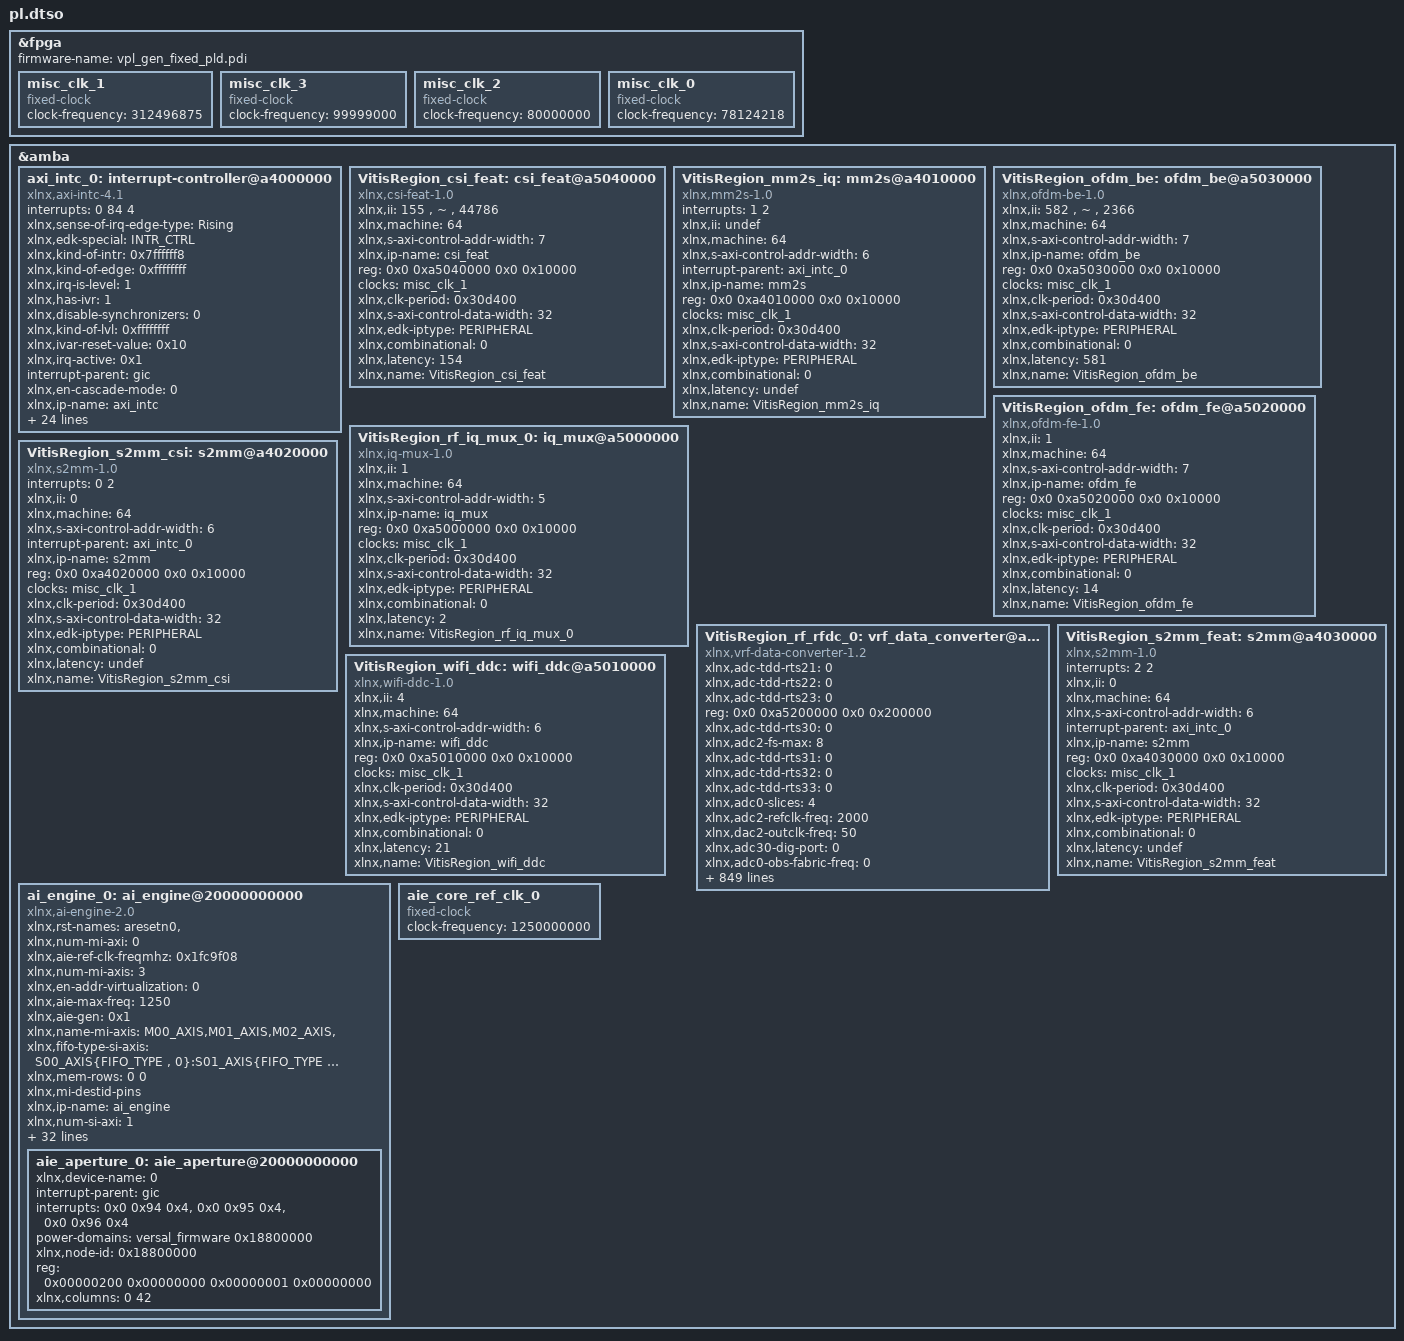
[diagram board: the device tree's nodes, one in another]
/dts-v1/;
/plugin/;
&fpga {
	firmware-name = "vpl_gen_fixed_pld.pdi";
	misc_clk_1: misc_clk_1 {
		compatible = "fixed-clock";
		clock-frequency = <312496875>;
		#clock-cells = <0>;
	};
	misc_clk_3: misc_clk_3 {
		compatible = "fixed-clock";
		clock-frequency = <99999000>;
		#clock-cells = <0>;
	};
	misc_clk_2: misc_clk_2 {
		compatible = "fixed-clock";
		clock-frequency = <80000000>;
		#clock-cells = <0>;
	};
	misc_clk_0: misc_clk_0 {
		compatible = "fixed-clock";
		clock-frequency = <78124218>;
		#clock-cells = <0>;
	};
};

&amba {
	axi_intc_0: interrupt-controller@a4000000 {
		#interrupt-cells = <2>;
		interrupts = < 0 84 4 >;
		xlnx,sense-of-irq-edge-type = "Rising";
		xlnx,edk-special = "INTR_CTRL";
		xlnx,kind-of-intr = <0x7ffffff8>;
		xlnx,kind-of-edge = <0xffffffff>;
		xlnx,irq-is-level = <1>;
		xlnx,has-ivr = <1>;
		compatible = "xlnx,axi-intc-4.1" , "xlnx,xps-intc-1.00.a";
		xlnx,disable-synchronizers = <0>;
		xlnx,kind-of-lvl = <0xffffffff>;
		xlnx,ivar-reset-value = <0x10>;
		xlnx,irq-active = <0x1>;
		interrupt-parent = <&gic>;
		xlnx,en-cascade-mode = <0>;
		xlnx,ip-name = "axi_intc";
		xlnx,has-ilr = <0>;
		reg = <0x0 0xa4000000 0x0 0x10000>;
		xlnx,addr-width = <0x20>;
		clocks = <&misc_clk_0>;
		xlnx,s-axi-aclk-freq-mhz = <0x4a814ba>;
		xlnx,num-sw-intr = <0>;
		xlnx,irq-connection = <1>;
		xlnx,num-intr-inputs = <0x1f>;
		xlnx,has-sie = <1>;
		xlnx,enable-async = <0>;
		xlnx,has-cie = <1>;
		xlnx,num-sync-ff = <2>;
		xlnx,edk-iptype = "PERIPHERAL";
		xlnx,mb-clk-not-connected = <1>;
		xlnx,has-ipr = <1>;
		xlnx,sense-of-irq-level-type = "Active_High";
		xlnx,cascade-master = <0>;
		xlnx,processor-clk-freq-mhz = <100>;
		xlnx,is-fast = <0x0>;
		clock-names = "s_axi_aclk";
		xlnx,has-fast = <0>;
		xlnx,ivar-rst-val = <0x10>;
		interrupt-controller;
		interrupt-names = "irq";
		xlnx,async-intr = <0xffffffff>;
		xlnx,name = "axi_intc_0";
	};
	VitisRegion_csi_feat: csi_feat@a5040000 {
		compatible = "xlnx,csi-feat-1.0";
		xlnx,ii = "155 , ~ , 44786";
		xlnx,machine = <64>;
		xlnx,s-axi-control-addr-width = <7>;
		xlnx,ip-name = "csi_feat";
		reg = <0x0 0xa5040000 0x0 0x10000>;
		clocks = <&misc_clk_1>;
		xlnx,clk-period = <0x30d400>;
		xlnx,s-axi-control-data-width = <32>;
		xlnx,edk-iptype = "PERIPHERAL";
		clock-names = "ap_clk";
		xlnx,combinational = <0>;
		xlnx,latency = <154>;
		xlnx,name = "VitisRegion_csi_feat";
	};
	VitisRegion_mm2s_iq: mm2s@a4010000 {
		interrupts = < 1 2 >;
		compatible = "xlnx,mm2s-1.0";
		xlnx,ii = "undef";
		xlnx,machine = <64>;
		xlnx,s-axi-control-addr-width = <6>;
		interrupt-parent = <&axi_intc_0>;
		xlnx,ip-name = "mm2s";
		reg = <0x0 0xa4010000 0x0 0x10000>;
		clocks = <&misc_clk_1>;
		xlnx,clk-period = <0x30d400>;
		xlnx,s-axi-control-data-width = <32>;
		xlnx,edk-iptype = "PERIPHERAL";
		clock-names = "ap_clk";
		interrupt-names = "interrupt";
		xlnx,combinational = <0>;
		xlnx,latency = "undef";
		xlnx,name = "VitisRegion_mm2s_iq";
	};
	VitisRegion_ofdm_be: ofdm_be@a5030000 {
		compatible = "xlnx,ofdm-be-1.0";
		xlnx,ii = "582 , ~ , 2366";
		xlnx,machine = <64>;
		xlnx,s-axi-control-addr-width = <7>;
		xlnx,ip-name = "ofdm_be";
		reg = <0x0 0xa5030000 0x0 0x10000>;
		clocks = <&misc_clk_1>;
		xlnx,clk-period = <0x30d400>;
		xlnx,s-axi-control-data-width = <32>;
		xlnx,edk-iptype = "PERIPHERAL";
		clock-names = "ap_clk";
		xlnx,combinational = <0>;
		xlnx,latency = <581>;
		xlnx,name = "VitisRegion_ofdm_be";
	};
	VitisRegion_ofdm_fe: ofdm_fe@a5020000 {
		compatible = "xlnx,ofdm-fe-1.0";
		xlnx,ii = <1>;
		xlnx,machine = <64>;
		xlnx,s-axi-control-addr-width = <7>;
		xlnx,ip-name = "ofdm_fe";
		reg = <0x0 0xa5020000 0x0 0x10000>;
		clocks = <&misc_clk_1>;
		xlnx,clk-period = <0x30d400>;
		xlnx,s-axi-control-data-width = <32>;
		xlnx,edk-iptype = "PERIPHERAL";
		clock-names = "ap_clk";
		xlnx,combinational = <0>;
		xlnx,latency = <14>;
		xlnx,name = "VitisRegion_ofdm_fe";
	};
	VitisRegion_rf_iq_mux_0: iq_mux@a5000000 {
		compatible = "xlnx,iq-mux-1.0";
		xlnx,ii = <1>;
		xlnx,machine = <64>;
		xlnx,s-axi-control-addr-width = <5>;
		xlnx,ip-name = "iq_mux";
		reg = <0x0 0xa5000000 0x0 0x10000>;
		clocks = <&misc_clk_1>;
		xlnx,clk-period = <0x30d400>;
		xlnx,s-axi-control-data-width = <32>;
		xlnx,edk-iptype = "PERIPHERAL";
		clock-names = "ap_clk";
		xlnx,combinational = <0>;
		xlnx,latency = <2>;
		xlnx,name = "VitisRegion_rf_iq_mux_0";
	};
	VitisRegion_rf_rfdc_0: vrf_data_converter@a5200000 {
		xlnx,adc-tdd-rts21 = <0>;
		xlnx,adc-tdd-rts22 = <0>;
		xlnx,adc-tdd-rts23 = <0>;
		reg = <0x0 0xa5200000 0x0 0x200000>;
		xlnx,adc-tdd-rts30 = <0>;
		xlnx,adc2-fs-max = <8>;
		xlnx,adc-tdd-rts31 = <0>;
		xlnx,adc-tdd-rts32 = <0>;
		xlnx,adc-tdd-rts33 = <0>;
		xlnx,adc0-slices = <4>;
		xlnx,adc2-refclk-freq = <2000>;
		xlnx,dac2-outclk-freq = <50>;
		xlnx,adc30-dig-port = <0>;
		xlnx,adc0-obs-fabric-freq = <0>;
		xlnx,dac2-band = <0>;
		clock-names = "m0_axis_aclk" , "s_axi_aclk";
		xlnx,adc-obs-data-width00 = <8>;
		xlnx,adc-obs-data-width01 = <8>;
		xlnx,adc-obs-data-width02 = <8>;
		xlnx,adc-coarse-mixer1-freq00 = <0>;
		xlnx,adc-obs-data-width03 = <8>;
		xlnx,adc-coarse-mixer1-freq01 = <0>;
		xlnx,adc-coarse-mixer1-freq02 = <0>;
		xlnx,adc-coarse-mixer1-freq03 = <0>;
		xlnx,adc-obs-data-width10 = <8>;
		xlnx,adc-obs-data-width11 = <8>;
		xlnx,adc-obs-data-width12 = <8>;
		xlnx,adc-coarse-mixer1-freq10 = <0>;
		xlnx,adc-obs-data-width13 = <8>;
		xlnx,mem-init-file-adc = "none";
		xlnx,adc-coarse-mixer1-freq11 = <0>;
		xlnx,adc-calopt-mode00 = <1>;
		xlnx,adc-coarse-mixer1-freq12 = <0>;
		xlnx,adc-calopt-mode01 = <1>;
		xlnx,dac3-fbdiv = <10>;
		xlnx,adc-coarse-mixer1-freq13 = <0>;
		xlnx,adc-calopt-mode02 = <1>;
		xlnx,adc-calopt-mode03 = <1>;
		xlnx,dac0-interpolation = <0>;
		xlnx,adc-obs-data-width20 = <8>;
		xlnx,adc-nco-freq00 = <0x252f88>;
		xlnx,adc-obs-data-width21 = <8>;
		xlnx,adc-nco-freq01 = <0>;
		xlnx,adc-obs-data-width22 = <8>;
		xlnx,adc-coarse-mixer1-freq20 = <0>;
		xlnx,adc-nco-freq02 = <0>;
		xlnx,adc-obs-data-width23 = <8>;
		xlnx,adc-coarse-mixer1-freq21 = <0>;
		xlnx,adc-calopt-mode10 = <1>;
		xlnx,adc-nco-freq03 = <0>;
		xlnx,dac1-vop = <24>;
		xlnx,adc-coarse-mixer1-freq22 = <0>;
		xlnx,adc-calopt-mode11 = <1>;
		xlnx,dac-mixer-mode00 = <2>;
		xlnx,adc-coarse-mixer1-freq23 = <0>;
		xlnx,adc-calopt-mode12 = <1>;
		xlnx,dac-mixer-mode01 = <2>;
		xlnx,adc-calopt-mode13 = <1>;
		xlnx,dac-mixer-mode02 = <2>;
		xlnx,dac-mixer-mode03 = <2>;
		xlnx,adc-obs-data-width30 = <8>;
		xlnx,adc-nco-freq10 = <0>;
		xlnx,adc-obs-data-width31 = <8>;
		xlnx,adc-nco-freq11 = <0>;
		xlnx,adc-obs-data-width32 = <8>;
		xlnx,dac2-fbdiv = <10>;
		xlnx,adc-coarse-mixer1-freq30 = <0>;
		xlnx,adc-nco-freq12 = <0>;
		xlnx,adc-obs-data-width33 = <8>;
		xlnx,adc-coarse-mixer1-freq31 = <0>;
		xlnx,adc-calopt-mode20 = <1>;
		xlnx,adc-nco-freq13 = <0>;
		xlnx,adc-coarse-mixer1-freq32 = <0>;
		xlnx,adc-calopt-mode21 = <1>;
		xlnx,dac-mixer-mode10 = <2>;
		xlnx,adc-coarse-mixer1-freq33 = <0>;
		xlnx,adc-calopt-mode22 = <1>;
		xlnx,dac-mixer-mode11 = <2>;
		xlnx,adc-calopt-mode23 = <1>;
		xlnx,dac-mixer-mode12 = <2>;
		xlnx,dac-mixer-mode13 = <2>;
		xlnx,adc-nco-freq20 = <0>;
		xlnx,adc-nco-freq21 = <0>;
		xlnx,adc-nco-freq22 = <0>;
		xlnx,adc-calopt-mode30 = <1>;
		xlnx,adc-nco-freq23 = <0>;
		xlnx,adc-calopt-mode31 = <1>;
		xlnx,dac-mixer-mode20 = <2>;
		xlnx,adc-calopt-mode32 = <1>;
		xlnx,adc0-fabric-freq = <80>;
		xlnx,dac-mixer-mode21 = <2>;
		xlnx,adc-calopt-mode33 = <1>;
		xlnx,dac-mixer-mode22 = <2>;
		xlnx,dac1-fbdiv = <10>;
		xlnx,dac-mixer-mode23 = <2>;
		xlnx,adc-nco-freq30 = <0>;
		xlnx,adc-nco-freq31 = <0>;
		xlnx,adc3-outclk-freq = <0x1dcd650>;
		xlnx,adc-nco-freq32 = <0>;
		xlnx,adc-nco-freq33 = <0>;
		xlnx,dac-mixer-mode30 = <2>;
		xlnx,adc23-dig-port = <0>;
		xlnx,dac-mixer-mode31 = <2>;
		xlnx,dac-mixer-mode32 = <2>;
		xlnx,dac-mixer-mode33 = <2>;
		xlnx,adc-data-type00 = <1>;
		xlnx,dac-channelizer-init-file = <0>;
		xlnx,adc-data-type01 = <0>;
		xlnx,adc-data-type02 = <0>;
		xlnx,dac0-fbdiv = <10>;
		xlnx,adc-data-type03 = <0>;
		xlnx,adc0-decimation = <40>;
		xlnx,adc-data-type10 = <0>;
		xlnx,dac3-enable = <0>;
		xlnx,adc-data-type11 = <0>;
		xlnx,adc-data-type12 = <0>;
		xlnx,adc-data-type13 = <0>;
		xlnx,adc-data-type20 = <0>;
		xlnx,adc-data-type21 = <0>;
		xlnx,adc0-link-coupling = <0>;
		xlnx,adc-data-type22 = <0>;
		xlnx,adc-data-type23 = <0>;
		xlnx,adc3-vco = <8500>;
		xlnx,adc-data-type30 = <0>;
		xlnx,adc-data-type31 = <0>;
		xlnx,adc0-clock-dist = <0>;
		xlnx,adc-data-type32 = <0>;
		xlnx,adc1-decimation = <0>;
		xlnx,adc-data-type33 = <0>;
		xlnx,adc20-dig-port = <0>;
		xlnx,adc1-fs-max = <8>;
		xlnx,adc3-sampling-rate = <2>;
		xlnx,dac0-link-coupling = <0>;
		xlnx,adc1-clock-dist = <0>;
		xlnx,adc2-decimation = <0>;
		xlnx,dac-pre-interp00 = <0>;
		xlnx,dac3-sampling-rate = <0x61a800>;
		xlnx,dac-pre-interp01 = <0>;
		xlnx,dac-pre-interp02 = <0>;
		xlnx,dac-pre-interp03 = <0>;
		xlnx,dac2-refclk-freq = <6400>;
		xlnx,dac-pre-interp10 = <0>;
		xlnx,adc-nco1-phase00 = <0>;
		xlnx,dac-pre-interp11 = <0>;
		xlnx,adc-nco1-phase01 = <0>;
		xlnx,dac-pre-interp12 = <0>;
		xlnx,adc-nco1-phase02 = <0>;
		xlnx,dac-pre-interp13 = <0>;
		xlnx,adc-nco1-phase03 = <0>;
		xlnx,adc2-clock-dist = <0>;
		xlnx,dac0-refclk-div = <1>;
		xlnx,dac-pre-interp20 = <0>;
		xlnx,adc3-decimation = <0>;
		xlnx,adc-nco1-phase10 = <0>;
		xlnx,dac-pre-interp21 = <0>;
		xlnx,adc-nco1-phase11 = <0>;
		xlnx,dac-pre-interp22 = <0>;
		xlnx,adc-nco1-phase12 = <0>;
		xlnx,dac-pre-interp23 = <0>;
		xlnx,adc-nco1-phase13 = <0>;
		xlnx,dac-pre-interp30 = <0>;
		xlnx,adc-nco1-phase20 = <0>;
		xlnx,dac-pre-interp31 = <0>;
		xlnx,adc-nco1-phase21 = <0>;
		xlnx,dac-pre-interp32 = <0>;
		xlnx,adc-nco1-phase22 = <0>;
		xlnx,dac-pre-interp33 = <0>;
		xlnx,adc-mixer-type00 = <2>;
		xlnx,adc-nco1-phase23 = <0>;
		xlnx,adc-mixer-type01 = <3>;
		xlnx,adc-mixer-type02 = <3>;
		xlnx,adc-mixer-type03 = <3>;
		xlnx,adc-nco1-phase30 = <0>;
		xlnx,adc-nco1-phase31 = <0>;
		xlnx,adc-nco1-phase32 = <0>;
		xlnx,adc-mixer-type10 = <3>;
		xlnx,adc-nco1-phase33 = <0>;
		xlnx,adc-mixer-type11 = <3>;
		xlnx,adc2-band = <0>;
		xlnx,adc-mixer-type12 = <3>;
		xlnx,adc3-clock-dist = <0>;
		xlnx,adc-mixer-type13 = <3>;
		xlnx,dac1-refclk-div = <1>;
		xlnx,adc13-dig-port = <0>;
		xlnx,adc0-pll-enable;
		xlnx,adc-mixer-type20 = <3>;
		xlnx,adc-mixer-type21 = <3>;
		xlnx,adc-mixer-type22 = <3>;
		xlnx,adc-mixer-type23 = <3>;
		xlnx,adc-mixer-type30 = <3>;
		xlnx,adc-mixer-type31 = <3>;
		xlnx,adc-mixer-type32 = <3>;
		xlnx,dac-sysref-source = <0>;
		xlnx,adc-mixer-type33 = <3>;
		xlnx,dac2-refclk-div = <1>;
		xlnx,dac0-fabric-freq = <0>;
		xlnx,adc3-refclk-freq = <2000>;
		xlnx,adc10-dig-port = <0>;
		xlnx,dac3-outclk-freq = <50>;
		xlnx,dac2-enable = <0>;
		xlnx,freq-hop-enable;
		xlnx,dac3-refclk-div = <1>;
		xlnx,adc-channelizer-init-file = <0>;
		xlnx,dac-coarse-mixer-freq00 = <0>;
		xlnx,dac-coarse-mixer-freq01 = <0>;
		xlnx,adc0-fs-max = <8>;
		xlnx,dac-coarse-mixer-freq02 = <0>;
		xlnx,mem-init-file-dac = "none";
		xlnx,dac-coarse-mixer-freq03 = <0>;
		xlnx,dac-coarse-mixer-freq10 = <0>;
		xlnx,dac-coarse-mixer-freq11 = <0>;
		xlnx,dac-coarse-mixer-freq12 = <0>;
		xlnx,dac-coarse-mixer-freq13 = <0>;
		xlnx,dac-coarse-mixer-freq20 = <0>;
		xlnx,adc2-obs-fabric-freq = <0>;
		xlnx,dac-coarse-mixer-freq21 = <0>;
		xlnx,dac3-outdiv = <1>;
		xlnx,dac-coarse-mixer-freq22 = <0>;
		xlnx,dac-coarse-mixer-freq23 = <0>;
		xlnx,dac-coarse-mixer-freq30 = <0>;
		xlnx,dac-coarse-mixer-freq31 = <0>;
		xlnx,dac-coarse-mixer-freq32 = <0>;
		xlnx,dac-coarse-mixer-freq33 = <0>;
		xlnx,adc-coarse-mixer-freq00 = <3>;
		xlnx,adc-coarse-mixer-freq01 = <0>;
		xlnx,adc1-fabric-freq = <0>;
		xlnx,adc-coarse-mixer-freq02 = <0>;
		xlnx,adc-coarse-mixer-freq03 = <0>;
		xlnx,adc-channelizer-position = <2>;
		xlnx,dac-mode00 = <0>;
		xlnx,dac-nyquist00 = <0>;
		xlnx,dac-mode01 = <0>;
		xlnx,dac-nco-phase00 = <0>;
		xlnx,dac-nyquist01 = <0>;
		xlnx,dac-mode02 = <0>;
		xlnx,dac-nco-phase01 = <0>;
		xlnx,dac-nyquist02 = <0>;
		xlnx,dac-mode03 = <0>;
		xlnx,dac-nco-phase02 = <0>;
		xlnx,dac-nyquist03 = <0>;
		xlnx,adc1-vco = <8500>;
		xlnx,adc03-dig-port = <0>;
		xlnx,dac-nco-phase03 = <0>;
		xlnx,adc-coarse-mixer-freq10 = <0>;
		xlnx,adc-coarse-mixer-freq11 = <0>;
		xlnx,adc-coarse-mixer-freq12 = <0>;
		xlnx,adc-coarse-mixer-freq13 = <0>;
		xlnx,dac-mode10 = <0>;
		xlnx,dac-nyquist10 = <0>;
		xlnx,dac-mode11 = <0>;
		xlnx,dac-nco1-phase00 = <0>;
		xlnx,dac-nco-phase10 = <0>;
		xlnx,dac-nyquist11 = <0>;
		xlnx,dac-mode12 = <0>;
		xlnx,dac-nco1-phase01 = <0>;
		xlnx,dac-nco-phase11 = <0>;
		xlnx,dac-nyquist12 = <0>;
		xlnx,dac-mode13 = <0>;
		xlnx,dac-nco1-phase02 = <0>;
		xlnx,dac-nco-phase12 = <0>;
		xlnx,dac-nyquist13 = <0>;
		xlnx,dac-nco1-phase03 = <0>;
		xlnx,dac-nco-phase13 = <0>;
		xlnx,adc-coarse-mixer-freq20 = <0>;
		xlnx,adc-coarse-mixer-freq21 = <0>;
		xlnx,adc-coarse-mixer-freq22 = <0>;
		xlnx,adc-coarse-mixer-freq23 = <0>;
		xlnx,dac-mode20 = <0>;
		xlnx,dac-nyquist20 = <0>;
		xlnx,dac-mode21 = <0>;
		xlnx,dac-nco1-phase10 = <0>;
		xlnx,dac-nco-phase20 = <0>;
		xlnx,dac-nyquist21 = <0>;
		xlnx,dac-mode22 = <0>;
		xlnx,dac-nco1-phase11 = <0>;
		xlnx,dac-nco-phase21 = <0>;
		xlnx,dac-nyquist22 = <0>;
		xlnx,dac-mode23 = <0>;
		xlnx,dac-nco1-phase12 = <0>;
		xlnx,dac-nco-phase22 = <0>;
		xlnx,dac-nyquist23 = <0>;
		xlnx,dac-nco1-phase13 = <0>;
		xlnx,dac-nco-phase23 = <0>;
		xlnx,adc-coarse-mixer-freq30 = <0>;
		xlnx,adc-coarse-mixer-freq31 = <0>;
		xlnx,dac3-slices = <4>;
		xlnx,adc-coarse-mixer-freq32 = <0>;
		xlnx,adc-coarse-mixer-freq33 = <0>;
		xlnx,dac-mode30 = <0>;
		xlnx,dac-nyquist30 = <0>;
		xlnx,dac-mode31 = <0>;
		xlnx,dac-nco1-phase20 = <0>;
		xlnx,dac-nco-phase30 = <0>;
		xlnx,dac-nyquist31 = <0>;
		xlnx,dac-mode32 = <0>;
		xlnx,dac-nco1-phase21 = <0>;
		xlnx,dac-nco-phase31 = <0>;
		xlnx,dac-nyquist32 = <0>;
		xlnx,dac-mode33 = <0>;
		xlnx,dac-nco1-phase22 = <0>;
		xlnx,dac-nco-freq00 = <0>;
		xlnx,dac-nco-phase32 = <0>;
		xlnx,dac-nyquist33 = <0>;
		xlnx,dac-mixer-type00 = <3>;
		xlnx,dac-nco1-freq00 = <0>;
		xlnx,dac-nco1-phase23 = <0>;
		xlnx,dac-nco-freq01 = <0>;
		xlnx,dac-nco-phase33 = <0>;
		xlnx,adc3-clock-source = <3>;
		xlnx,dac-mixer-type01 = <3>;
		xlnx,dac-nco1-freq01 = <0>;
		xlnx,dac-nco-freq02 = <0>;
		xlnx,adc2-sampling-rate = <2>;
		xlnx,dac-mixer-type02 = <3>;
		xlnx,dac-nco1-freq02 = <0>;
		xlnx,dac-nco-freq03 = <0>;
		xlnx,dac-mixer-type03 = <3>;
		xlnx,dac-nco1-freq03 = <0>;
		xlnx,adc31-dig-port = <0>;
		xlnx,dac-nco1-phase30 = <0>;
		xlnx,pl-clock-freq = <100>;
		xlnx,dac-nco1-phase31 = <0>;
		xlnx,dac-nco1-phase32 = <0>;
		xlnx,dac-nco-freq10 = <0>;
		xlnx,dac-mixer-type10 = <3>;
		xlnx,dac-nco1-freq10 = <0>;
		xlnx,dac-nco1-phase33 = <0>;
		xlnx,dac-nco-freq11 = <0>;
		xlnx,adc00-dig-port = <1>;
		xlnx,dac-mixer-type11 = <3>;
		xlnx,dac-nco1-freq11 = <0>;
		xlnx,dac-nco-freq12 = <0>;
		xlnx,edk-iptype = "PERIPHERAL";
		xlnx,dac-mixer-type12 = <3>;
		xlnx,dac-nco1-freq12 = <0>;
		xlnx,dac-nco-freq13 = <0>;
		xlnx,dac-mixer-type13 = <3>;
		xlnx,dac-nco1-freq13 = <0>;
		xlnx,dac-nco-freq20 = <0>;
		xlnx,dac-mixer-type20 = <3>;
		xlnx,dac-nco1-freq20 = <0>;
		xlnx,dac-nco-freq21 = <0>;
		xlnx,dac-mixer-type21 = <3>;
		xlnx,dac-nco1-freq21 = <0>;
		xlnx,dac-nco-freq22 = <0>;
		xlnx,dac-mixer-type22 = <3>;
		xlnx,dac-nco1-freq22 = <0>;
		xlnx,dac-nco-freq23 = <0>;
		xlnx,dac-mixer-type23 = <3>;
		xlnx,dac-nco1-freq23 = <0>;
		xlnx,adc2-clock-source = <2>;
		xlnx,adc2-dlc = <0>;
		xlnx,dac2-sampling-rate = <0x61a800>;
		xlnx,dac-nco-freq30 = <0>;
		xlnx,dac-mixer-type30 = <3>;
		xlnx,dac-nco1-freq30 = <0>;
		xlnx,dac-nco-freq31 = <0>;
		xlnx,dac-mixer-type31 = <3>;
		xlnx,dac-nco1-freq31 = <0>;
		xlnx,dac-nco-freq32 = <0>;
		xlnx,dac-mixer-type32 = <3>;
		xlnx,dac-nco1-freq32 = <0>;
		xlnx,dac-nco-freq33 = <0>;
		xlnx,dac2-vco = <8500>;
		xlnx,dac-mixer-type33 = <3>;
		xlnx,dac-nco1-freq33 = <0>;
		xlnx,dac1-band = <0>;
		xlnx,dac1-enable = <0>;
		xlnx,elaboration-dir = <0>;
		xlnx,adc1-clock-source = <1>;
		compatible = "xlnx,vrf-data-converter-1.2";
		xlnx,dac3-refclk-freq = <6400>;
		xlnx,dac-debug = <0>;
		xlnx,dac-second-stage-duc-mix00 = <0>;
		xlnx,dac-second-stage-duc-mix01 = <0>;
		xlnx,dac-second-stage-duc-mix02 = <0>;
		xlnx,dac-second-stage-duc-mix03 = <0>;
		xlnx,dac-second-stage-duc-mix10 = <0>;
		xlnx,adc3-enable = <0>;
		xlnx,dac-second-stage-duc-mix11 = <0>;
		xlnx,dac-second-stage-duc-mix12 = <0>;
		xlnx,dac-second-stage-duc-mix13 = <0>;
		xlnx,adc0-clock-source = <0>;
		xlnx,dac-second-stage-duc-mix20 = <0>;
		xlnx,dac-second-stage-duc-mix21 = <0>;
		xlnx,dac-second-stage-duc-mix22 = <0>;
		xlnx,dac-second-stage-duc-mix23 = <0>;
		xlnx,dac-second-stage-duc-mix30 = <0>;
		xlnx,dac-second-stage-duc-mix31 = <0>;
		xlnx,dac2-outdiv = <1>;
		xlnx,dac-second-stage-duc-mix32 = <0>;
		xlnx,dac-second-stage-duc-mix33 = <0>;
		xlnx,adc0-outclk-freq = <100>;
		xlnx,adc-obs-decimation-mode00 = <1>;
		xlnx,adc-obs-decimation-mode01 = <0>;
		xlnx,adc-obs-decimation-mode02 = <0>;
		xlnx,adc-obs-decimation-mode03 = <0>;
		xlnx,adc-obs-decimation-mode10 = <1>;
		xlnx,adc-obs-decimation-mode11 = <1>;
		xlnx,adc-obs-decimation-mode12 = <1>;
		xlnx,adc-obs-decimation-mode13 = <1>;
		xlnx,vnc-enables = <110000>;
		xlnx,adc21-dig-port = <0>;
		xlnx,adc-obs-decimation-mode20 = <1>;
		xlnx,adc-obs-decimation-mode21 = <1>;
		xlnx,dac1-fabric-freq = <0>;
		xlnx,dac3-interpolation = <0>;
		xlnx,adc-obs-decimation-mode22 = <1>;
		xlnx,adc-obs-decimation-mode23 = <1>;
		xlnx,adc-obs-decimation-mode30 = <1>;
		xlnx,adc-band-self00 = <0>;
		xlnx,adc-obs-decimation-mode31 = <1>;
		xlnx,adc-band-self01 = <1>;
		xlnx,adc-obs-decimation-mode32 = <1>;
		xlnx,dac2-slices = <4>;
		xlnx,adc-band-self02 = <1>;
		xlnx,adc-obs-decimation-mode33 = <1>;
		xlnx,adc-band-self03 = <1>;
		xlnx,adc-dither00;
		xlnx,adc-dither01;
		xlnx,adc-dither02;
		xlnx,adc-dither03;
		xlnx,adc-band-self10 = <1>;
		xlnx,adc-band-self11 = <1>;
		xlnx,adc-band-self12 = <1>;
		xlnx,dac2-vop = <24>;
		xlnx,adc-band-self13 = <1>;
		xlnx,adc-dither10;
		xlnx,adc-dither11;
		xlnx,adc-dither12;
		xlnx,adc-dither13;
		xlnx,adc-band-self20 = <1>;
		xlnx,adc-band-self21 = <1>;
		xlnx,adc-band-self22 = <1>;
		xlnx,adc-band-self23 = <1>;
		xlnx,adc-dither20;
		xlnx,adc-dither21;
		xlnx,adc-dither22;
		xlnx,adc-dither23;
		xlnx,adc-band-self30 = <1>;
		xlnx,adc-band-self31 = <1>;
		xlnx,adc-band-self32 = <1>;
		xlnx,adc-band-self33 = <1>;
		xlnx,adc-dither30;
		xlnx,adc-dither31;
		xlnx,adc-dither32;
		xlnx,adc-dither33;
		xlnx,dac0-enable = <0>;
		xlnx,adc3-link-coupling = <0>;
		xlnx,adc2-fabric-freq = <0>;
		xlnx,name = "VitisRegion_rf_rfdc_0";
		xlnx,adc-data-width00 = <2>;
		xlnx,adc-data-width01 = <13>;
		xlnx,adc-data-width02 = <13>;
		xlnx,adc2-enable = <0>;
		xlnx,adc-data-width03 = <13>;
		xlnx,adc3-fbdiv = <10>;
		xlnx,adc1-band = <0>;
		xlnx,dac3-link-coupling = <0>;
		xlnx,adc-data-width10 = <8>;
		xlnx,adc-data-width11 = <8>;
		xlnx,adc-data-width12 = <8>;
		xlnx,adc-data-width13 = <8>;
		xlnx,adc1-sampling-rate = <2>;
		xlnx,adc-data-width20 = <8>;
		xlnx,adc-data-width21 = <8>;
		xlnx,adc-data-width22 = <8>;
		xlnx,adc0-dlc = <0>;
		xlnx,adc-data-width23 = <8>;
		xlnx,dac1-outdiv = <1>;
		xlnx,adc2-fbdiv = <10>;
		xlnx,adc-debug = <0>;
		xlnx,dac0-vco = <8500>;
		xlnx,adc-data-width30 = <8>;
		xlnx,adc-data-width31 = <8>;
		xlnx,adc-data-width32 = <8>;
		xlnx,adc-data-width33 = <8>;
		xlnx,adc11-dig-port = <0>;
		xlnx,dac-data-type00 = <0>;
		xlnx,dac-tdd-rts00 = <0>;
		xlnx,dac-data-type01 = <0>;
		xlnx,dac-tdd-rts01 = <0>;
		xlnx,dac-data-type02 = <0>;
		xlnx,dac-tdd-rts02 = <0>;
		xlnx,adc1-fbdiv = <10>;
		xlnx,dac-data-type03 = <0>;
		xlnx,dac-tdd-rts03 = <0>;
		xlnx,dac1-sampling-rate = <0x61a800>;
		xlnx,dac-data-type10 = <0>;
		xlnx,dac-tdd-rts10 = <0>;
		xlnx,dac-data-type11 = <0>;
		xlnx,dac-tdd-rts11 = <0>;
		xlnx,dac-data-type12 = <0>;
		xlnx,dac-tdd-rts12 = <0>;
		xlnx,dac-data-type13 = <0>;
		xlnx,dac-tdd-rts13 = <0>;
		xlnx,adc3-outdiv = <1>;
		xlnx,adc0-refclk-freq = <200>;
		xlnx,adc0-fbdiv = <64>;
		xlnx,dac-data-type20 = <0>;
		xlnx,dac-tdd-rts20 = <0>;
		xlnx,dac-data-type21 = <0>;
		xlnx,dac-tdd-rts21 = <0>;
		xlnx,dac0-outclk-freq = <50>;
		xlnx,dac-data-type22 = <0>;
		xlnx,dac-tdd-rts22 = <0>;
		xlnx,dac-data-type23 = <0>;
		xlnx,dac-tdd-rts23 = <0>;
		xlnx,dac3-fs-max = <16>;
		xlnx,dac-data-type30 = <0>;
		xlnx,dac-tdd-rts30 = <0>;
		xlnx,dac0-clock-dist = <0>;
		xlnx,dac-data-type31 = <0>;
		xlnx,dac-tdd-rts31 = <0>;
		xlnx,dac-data-type32 = <0>;
		xlnx,dac-tdd-rts32 = <0>;
		xlnx,dac-data-type33 = <0>;
		xlnx,dac-tdd-rts33 = <0>;
		xlnx,dac1-slices = <4>;
		xlnx,preset = "None";
		xlnx,dac1-clock-dist = <0>;
		xlnx,adc-first-stage-ddc-decimation00 = <1>;
		xlnx,adc-first-stage-ddc-decimation01 = <1>;
		xlnx,adc-first-stage-ddc-decimation02 = <1>;
		xlnx,adc3-slices = <4>;
		xlnx,adc-first-stage-ddc-decimation03 = <1>;
		xlnx,dac-interpolation-mode00 = <0>;
		xlnx,dac-interpolation-mode01 = <0>;
		xlnx,adc-first-stage-ddc-decimation10 = <0>;
		xlnx,dac-interpolation-mode02 = <0>;
		xlnx,adc-first-stage-ddc-decimation11 = <0>;
		xlnx,dac-interpolation-mode03 = <0>;
		xlnx,adc-first-stage-ddc-decimation12 = <0>;
		xlnx,adc-decimation-mode00 = <40>;
		xlnx,adc-first-stage-ddc-decimation13 = <0>;
		xlnx,adc-decimation-mode01 = <0>;
		xlnx,adc-decimation-mode02 = <0>;
		xlnx,adc-decimation-mode03 = <0>;
		xlnx,dac-interpolation-mode10 = <0>;
		xlnx,dac-interpolation-mode11 = <0>;
		xlnx,adc-first-stage-ddc-decimation20 = <0>;
		xlnx,dac-interpolation-mode12 = <0>;
		xlnx,adc-first-stage-ddc-decimation21 = <0>;
		xlnx,dac-interpolation-mode13 = <0>;
		xlnx,adc-first-stage-ddc-decimation22 = <0>;
		xlnx,dac2-clock-dist = <0>;
		xlnx,adc-decimation-mode10 = <0>;
		xlnx,adc-first-stage-ddc-decimation23 = <0>;
		xlnx,adc-decimation-mode11 = <0>;
		xlnx,adc-decimation-mode12 = <0>;
		xlnx,adc-decimation-mode13 = <0>;
		xlnx,dac-interpolation-mode20 = <0>;
		xlnx,dac-interpolation-mode21 = <0>;
		xlnx,adc-first-stage-ddc-decimation30 = <0>;
		xlnx,dac-interpolation-mode22 = <0>;
		xlnx,adc-first-stage-ddc-decimation31 = <0>;
		xlnx,dac-interpolation-mode23 = <0>;
		xlnx,adc-first-stage-ddc-decimation32 = <0>;
		xlnx,adc-decimation-mode20 = <0>;
		xlnx,adc-first-stage-ddc-decimation33 = <0>;
		xlnx,adc-decimation-mode21 = <0>;
		xlnx,adc-decimation-mode22 = <0>;
		xlnx,adc-decimation-mode23 = <0>;
		xlnx,dac-interpolation-mode30 = <0>;
		xlnx,adc1-outclk-freq = <0x1dcd650>;
		xlnx,dac-interpolation-mode31 = <0>;
		xlnx,dac-interpolation-mode32 = <0>;
		xlnx,dac-interpolation-mode33 = <0>;
		xlnx,adc-decimation-mode30 = <0>;
		xlnx,dac2-interpolation = <0>;
		xlnx,adc-decimation-mode31 = <0>;
		xlnx,adc1-obs-fabric-freq = <0>;
		xlnx,adc-decimation-mode32 = <0>;
		xlnx,adc-decimation-mode33 = <0>;
		xlnx,dac0-vop = <24>;
		xlnx,adc1-enable = <0>;
		xlnx,dac3-clock-dist = <0>;
		xlnx,adc32-dig-port = <0>;
		xlnx,adc01-dig-port = <0>;
		xlnx,dac2-fabric-freq = <0>;
		xlnx,dac3-clock-source = <7>;
		xlnx,vnc-include-fs2-change;
		xlnx,dac-second-stage-duc00 = <0>;
		xlnx,dac-second-stage-duc01 = <0>;
		xlnx,dac-data-width00 = <16>;
		xlnx,dac-second-stage-duc02 = <0>;
		xlnx,dac-data-width01 = <16>;
		xlnx,dac-decoder-mode00 = <1>;
		xlnx,dac-second-stage-duc03 = <0>;
		xlnx,dac-data-width02 = <16>;
		xlnx,dac-decoder-mode01 = <1>;
		xlnx,dac-data-width03 = <16>;
		xlnx,dac-decoder-mode02 = <1>;
		xlnx,dac0-outdiv = <1>;
		xlnx,dac-decoder-mode03 = <1>;
		xlnx,dac-vop-mode = <1>;
		xlnx,dac-second-stage-duc10 = <0>;
		xlnx,dac-second-stage-duc11 = <0>;
		xlnx,dac-data-width10 = <16>;
		xlnx,dac-second-stage-duc12 = <0>;
		xlnx,dac-data-width11 = <16>;
		xlnx,dac-decoder-mode10 = <1>;
		xlnx,dac-second-stage-duc13 = <0>;
		xlnx,ip-name = "vrf_data_converter";
		xlnx,dac-data-width12 = <16>;
		xlnx,dac-decoder-mode11 = <1>;
		xlnx,dac-data-width13 = <16>;
		xlnx,dac-decoder-mode12 = <1>;
		xlnx,adc-slice00-enable;
		xlnx,dac-decoder-mode13 = <1>;
		xlnx,dac-second-stage-duc20 = <0>;
		xlnx,dac-second-stage-duc21 = <0>;
		xlnx,dac-data-width20 = <16>;
		xlnx,dac-second-stage-duc22 = <0>;
		xlnx,dac-data-width21 = <16>;
		xlnx,dac-decoder-mode20 = <1>;
		xlnx,dac-second-stage-duc23 = <0>;
		xlnx,dac-coarse-mixer1-freq00 = <0>;
		xlnx,dac-data-width22 = <16>;
		xlnx,dac-decoder-mode21 = <1>;
		xlnx,dac2-clock-source = <6>;
		xlnx,dac-coarse-mixer1-freq01 = <0>;
		xlnx,dac-data-width23 = <16>;
		xlnx,dac-decoder-mode22 = <1>;
		xlnx,dac-coarse-mixer1-freq02 = <0>;
		xlnx,dac-decoder-mode23 = <1>;
		xlnx,dac-coarse-mixer1-freq03 = <0>;
		xlnx,dac3-band = <0>;
		xlnx,dac-second-stage-duc30 = <0>;
		xlnx,dac-second-stage-duc31 = <0>;
		xlnx,dac-data-width30 = <16>;
		xlnx,dac-second-stage-duc32 = <0>;
		xlnx,dac-data-width31 = <16>;
		xlnx,dac-decoder-mode30 = <1>;
		xlnx,dac-second-stage-duc33 = <0>;
		xlnx,adc-first-stage-ddc-mix00 = <7>;
		xlnx,dac-coarse-mixer1-freq10 = <0>;
		xlnx,dac-data-width32 = <16>;
		xlnx,dac-decoder-mode31 = <1>;
		xlnx,adc2-outdiv = <1>;
		xlnx,adc-first-stage-ddc-mix01 = <7>;
		xlnx,dac0-band = <0>;
		xlnx,dac-coarse-mixer1-freq11 = <0>;
		xlnx,dac-data-width33 = <16>;
		xlnx,dac-decoder-mode32 = <1>;
		xlnx,adc-first-stage-ddc-mix02 = <7>;
		xlnx,dac-coarse-mixer1-freq12 = <0>;
		xlnx,dac-decoder-mode33 = <1>;
		xlnx,adc-first-stage-ddc-mix03 = <7>;
		xlnx,dac-coarse-mixer1-freq13 = <0>;
		xlnx,adc-first-stage-ddc-mix10 = <7>;
		xlnx,dac-coarse-mixer1-freq20 = <0>;
		xlnx,rf-analyzer = <0>;
		xlnx,adc2-link-coupling = <0>;
		xlnx,adc-first-stage-ddc-mix11 = <7>;
		xlnx,dac2-fs-max = <16>;
		xlnx,dac-coarse-mixer1-freq21 = <0>;
		xlnx,adc0-refclk-div = <1>;
		xlnx,adc-first-stage-ddc-mix12 = <7>;
		xlnx,dac-coarse-mixer1-freq22 = <0>;
		xlnx,adc-first-stage-ddc-mix13 = <7>;
		xlnx,dac-coarse-mixer1-freq23 = <0>;
		xlnx,adc2-vco = <8500>;
		xlnx,dac1-clock-source = <5>;
		clocks = <&misc_clk_2>, <&misc_clk_3>;
		xlnx,adc-nyquist00 = <0>;
		xlnx,adc-first-stage-ddc-mix20 = <7>;
		xlnx,adc-nyquist01 = <0>;
		xlnx,dac-coarse-mixer1-freq30 = <0>;
		xlnx,adc-first-stage-ddc-mix21 = <7>;
		xlnx,adc-nyquist02 = <0>;
		xlnx,dac-coarse-mixer1-freq31 = <0>;
		xlnx,adc-first-stage-ddc-mix22 = <7>;
		xlnx,adc-nyquist03 = <0>;
		xlnx,dac-coarse-mixer1-freq32 = <0>;
		xlnx,adc-first-stage-ddc-mix23 = <7>;
		xlnx,dac-coarse-mixer1-freq33 = <0>;
		xlnx,dac0-refclk-freq = <6400>;
		xlnx,dac0-slices = <4>;
		xlnx,adc-nyquist10 = <0>;
		xlnx,adc-first-stage-ddc-mix30 = <7>;
		xlnx,adc-nyquist11 = <0>;
		xlnx,adc-first-stage-ddc-mix31 = <7>;
		xlnx,adc-nyquist12 = <0>;
		xlnx,adc-first-stage-ddc-mix32 = <7>;
		xlnx,adc-nyquist13 = <0>;
		xlnx,adc-first-stage-ddc-mix33 = <7>;
		xlnx,dac2-link-coupling = <0>;
		xlnx,adc-nyquist20 = <0>;
		xlnx,calibration-time = <10>;
		xlnx,adc1-refclk-div = <1>;
		xlnx,adc-nyquist21 = <0>;
		xlnx,adc-nyquist22 = <0>;
		xlnx,adc-nyquist23 = <0>;
		xlnx,dac0-clock-source = <4>;
		xlnx,adc0-sampling-rate = <0x61a800>;
		xlnx,adc3-fabric-freq = <0>;
		xlnx,adc-nyquist30 = <0>;
		xlnx,adc-nyquist31 = <0>;
		xlnx,adc-nyquist32 = <0>;
		xlnx,axiclk-freq = <100>;
		xlnx,adc-nyquist33 = <0>;
		xlnx,adc2-slices = <4>;
		xlnx,adc2-refclk-div = <1>;
		xlnx,dac0-sampling-rate = <0x61a800>;
		xlnx,adc3-dlc = <0>;
		xlnx,adc-first-stage-ddc00 = <0>;
		xlnx,adc22-dig-port = <0>;
		xlnx,adc-first-stage-ddc01 = <0>;
		xlnx,adc-first-stage-ddc02 = <0>;
		xlnx,dac3-vco = <8500>;
		xlnx,adc-first-stage-ddc03 = <0>;
		xlnx,adc-first-stage-ddc10 = <0>;
		xlnx,adc-first-stage-ddc11 = <0>;
		xlnx,adc-first-stage-ddc12 = <0>;
		xlnx,adc-first-stage-ddc13 = <0>;
		xlnx,adc-mode00 = <1>;
		xlnx,adc-mode01 = <0>;
		xlnx,adc-mode02 = <0>;
		xlnx,adc-mode03 = <0>;
		xlnx,adc3-refclk-div = <1>;
		xlnx,adc-first-stage-ddc20 = <0>;
		xlnx,adc-first-stage-ddc21 = <0>;
		xlnx,adc-first-stage-ddc22 = <0>;
		xlnx,adc-first-stage-ddc23 = <0>;
		xlnx,adc-mode10 = <0>;
		xlnx,adc0-enable = <1>;
		xlnx,adc-mode11 = <0>;
		xlnx,adc-mode12 = <0>;
		xlnx,adc-mode13 = <0>;
		xlnx,adc1-refclk-freq = <2000>;
		xlnx,production-simulation = <0>;
		xlnx,adc-first-stage-ddc30 = <0>;
		xlnx,adc-first-stage-ddc31 = <0>;
		xlnx,adc-first-stage-ddc32 = <0>;
		xlnx,dac1-outclk-freq = <50>;
		xlnx,adc-first-stage-ddc33 = <0>;
		xlnx,adc-mode20 = <0>;
		xlnx,adc-mode21 = <0>;
		xlnx,adc-mode22 = <0>;
		xlnx,disable-bg-cal-en = <1>;
		xlnx,adc-mode23 = <0>;
		xlnx,silicon-revision = <0>;
		xlnx,adc-mode30 = <0>;
		xlnx,adc-mode31 = <0>;
		xlnx,adc-mode32 = <0>;
		xlnx,adc-mode33 = <0>;
		xlnx,adc1-outdiv = <1>;
		xlnx,dac1-fs-max = <16>;
		xlnx,adc-nco-phase00 = <0>;
		xlnx,adc-nco-phase01 = <0>;
		xlnx,adc-nco-phase02 = <0>;
		xlnx,adc-nco-phase03 = <0>;
		xlnx,adc-nco-phase10 = <0>;
		xlnx,adc-nco-phase11 = <0>;
		xlnx,adc-nco-phase12 = <0>;
		xlnx,dac1-interpolation = <0>;
		xlnx,adc-nco-phase13 = <0>;
		xlnx,vnc-include-ois-change;
		xlnx,adc3-band = <0>;
		xlnx,adc-nco-phase20 = <0>;
		xlnx,adc-nco-phase21 = <0>;
		xlnx,adc-nco-phase22 = <0>;
		xlnx,adc-nco-phase23 = <0>;
		xlnx,adc0-band = <0>;
		xlnx,adc3-fs-max = <8>;
		xlnx,adc2-outclk-freq = <0x1dcd650>;
		xlnx,adc-nco-phase30 = <0>;
		xlnx,adc-nco-phase31 = <0>;
		xlnx,dac-second-stage-duc-interpolation00 = <0>;
		xlnx,adc-nco-phase32 = <0>;
		xlnx,dac-second-stage-duc-interpolation01 = <0>;
		xlnx,adc-nco1-freq00 = <0>;
		xlnx,adc-nco-phase33 = <0>;
		xlnx,dac-second-stage-duc-interpolation02 = <0>;
		xlnx,adc-nco1-freq01 = <0>;
		xlnx,dac-second-stage-duc-interpolation03 = <0>;
		xlnx,adc-nco1-freq02 = <0>;
		xlnx,adc-nco1-freq03 = <0>;
		xlnx,dac3-vop = <24>;
		xlnx,adc12-dig-port = <0>;
		xlnx,adc-sysref-source = <0>;
		xlnx,ip-type = <3>;
		xlnx,dac-second-stage-duc-interpolation10 = <0>;
		xlnx,adc1-slices = <4>;
		xlnx,dac-second-stage-duc-interpolation11 = <0>;
		xlnx,adc-nco1-freq10 = <0>;
		xlnx,dac-second-stage-duc-interpolation12 = <0>;
		xlnx,adc-nco1-freq11 = <0>;
		xlnx,dac-second-stage-duc-interpolation13 = <0>;
		xlnx,adc-nco1-freq12 = <0>;
		xlnx,adc-nco1-freq13 = <0>;
		xlnx,dac-second-stage-duc-interpolation20 = <0>;
		xlnx,dac3-fabric-freq = <0>;
		xlnx,high-speed-adc = <1>;
		xlnx,dac-second-stage-duc-interpolation21 = <0>;
		xlnx,adc-nco1-freq20 = <0>;
		xlnx,dac-second-stage-duc-interpolation22 = <0>;
		xlnx,adc-nco1-freq21 = <0>;
		xlnx,dac-second-stage-duc-interpolation23 = <0>;
		xlnx,adc-nco1-freq22 = <0>;
		xlnx,adc-nco1-freq23 = <0>;
		xlnx,dac-second-stage-duc-interpolation30 = <0>;
		xlnx,dac-second-stage-duc-interpolation31 = <0>;
		xlnx,adc-nco1-freq30 = <0>;
		xlnx,dac-second-stage-duc-interpolation32 = <0>;
		xlnx,adc0-vco = <12800>;
		xlnx,adc-nco1-freq31 = <0>;
		xlnx,dac-second-stage-duc-interpolation33 = <0>;
		xlnx,adc-nco1-freq32 = <0>;
		xlnx,adc-nco1-freq33 = <0>;
		xlnx,adc3-obs-fabric-freq = <0>;
		xlnx,adc1-link-coupling = <0>;
		xlnx,adc-mixer-mode00 = <0>;
		xlnx,adc-mixer-mode01 = <2>;
		xlnx,adc-mixer-mode02 = <2>;
		xlnx,adc-mixer-mode03 = <2>;
		xlnx,dac-band-self00 = <1>;
		xlnx,dac-band-self01 = <1>;
		xlnx,dac-band-self02 = <1>;
		xlnx,dac-band-self03 = <1>;
		xlnx,adc-mixer-mode10 = <2>;
		xlnx,adc-mixer-mode11 = <2>;
		xlnx,analog-detection = <1>;
		xlnx,adc-mixer-mode12 = <2>;
		xlnx,adc-mixer-mode13 = <2>;
		xlnx,dac-band-self10 = <1>;
		xlnx,dac-band-self11 = <1>;
		xlnx,dac-band-self12 = <1>;
		xlnx,dac-band-self13 = <1>;
		xlnx,adc-mixer-mode20 = <2>;
		xlnx,adc-mixer-mode21 = <2>;
		xlnx,adc-mixer-mode22 = <2>;
		xlnx,adc-mixer-mode23 = <2>;
		xlnx,dac1-link-coupling = <0>;
		xlnx,dac-band-self20 = <1>;
		xlnx,dac-band-self21 = <1>;
		xlnx,dac-band-self22 = <1>;
		xlnx,dac-band-self23 = <1>;
		xlnx,adc-mixer-mode30 = <2>;
		xlnx,adc-mixer-mode31 = <2>;
		xlnx,dac1-refclk-freq = <6400>;
		xlnx,adc-mixer-mode32 = <2>;
		xlnx,adc-mixer-mode33 = <2>;
		xlnx,dac-band-self30 = <1>;
		xlnx,dac-band-self31 = <1>;
		xlnx,dac-band-self32 = <1>;
		xlnx,dac-band-self33 = <1>;
		xlnx,adc1-dlc = <0>;
		xlnx,dac-channelizer-position = <0>;
		xlnx,dac1-vco = <8500>;
		xlnx,adc0-outdiv = <2>;
		xlnx,adc-tdd-rts00 = <0>;
		xlnx,adc-tdd-rts01 = <0>;
		xlnx,adc-tdd-rts02 = <0>;
		xlnx,dac0-fs-max = <16>;
		xlnx,adc-tdd-rts03 = <0>;
		xlnx,adc-tdd-rts10 = <0>;
		xlnx,adc33-dig-port = <0>;
		xlnx,adc-tdd-rts11 = <0>;
		xlnx,adc-tdd-rts12 = <0>;
		xlnx,adc-tdd-rts13 = <0>;
		xlnx,adc02-dig-port = <0>;
		xlnx,adc-tdd-rts20 = <0>;
		xlnx,component-name = "vitis_design_rfdc_0_0";
	};
	VitisRegion_s2mm_csi: s2mm@a4020000 {
		interrupts = < 0 2 >;
		compatible = "xlnx,s2mm-1.0";
		xlnx,ii = <0>;
		xlnx,machine = <64>;
		xlnx,s-axi-control-addr-width = <6>;
		interrupt-parent = <&axi_intc_0>;
		xlnx,ip-name = "s2mm";
		reg = <0x0 0xa4020000 0x0 0x10000>;
		clocks = <&misc_clk_1>;
		xlnx,clk-period = <0x30d400>;
		xlnx,s-axi-control-data-width = <32>;
		xlnx,edk-iptype = "PERIPHERAL";
		clock-names = "ap_clk";
		interrupt-names = "interrupt";
		xlnx,combinational = <0>;
		xlnx,latency = "undef";
		xlnx,name = "VitisRegion_s2mm_csi";
	};
	VitisRegion_s2mm_feat: s2mm@a4030000 {
		interrupts = < 2 2 >;
		compatible = "xlnx,s2mm-1.0";
		xlnx,ii = <0>;
		xlnx,machine = <64>;
		xlnx,s-axi-control-addr-width = <6>;
		interrupt-parent = <&axi_intc_0>;
		xlnx,ip-name = "s2mm";
		reg = <0x0 0xa4030000 0x0 0x10000>;
		clocks = <&misc_clk_1>;
		xlnx,clk-period = <0x30d400>;
		xlnx,s-axi-control-data-width = <32>;
		xlnx,edk-iptype = "PERIPHERAL";
		clock-names = "ap_clk";
		interrupt-names = "interrupt";
		xlnx,combinational = <0>;
		xlnx,latency = "undef";
		xlnx,name = "VitisRegion_s2mm_feat";
	};
	VitisRegion_wifi_ddc: wifi_ddc@a5010000 {
		compatible = "xlnx,wifi-ddc-1.0";
		xlnx,ii = <4>;
		xlnx,machine = <64>;
		xlnx,s-axi-control-addr-width = <6>;
		xlnx,ip-name = "wifi_ddc";
		reg = <0x0 0xa5010000 0x0 0x10000>;
		clocks = <&misc_clk_1>;
		xlnx,clk-period = <0x30d400>;
		xlnx,s-axi-control-data-width = <32>;
		xlnx,edk-iptype = "PERIPHERAL";
		clock-names = "ap_clk";
		xlnx,combinational = <0>;
		xlnx,latency = <21>;
		xlnx,name = "VitisRegion_wifi_ddc";
	};
	ai_engine_0: ai_engine@20000000000 {
		xlnx,rst-names = "aresetn0,";
		xlnx,num-mi-axi = <0>;
		compatible = "xlnx,ai-engine-2.0" , "xlnx,ai-engine-v2.0";
		xlnx,aie-ref-clk-freqmhz = <0x1fc9f08>;
		xlnx,num-mi-axis = <3>;
		xlnx,en-addr-virtualization = <0>;
		xlnx,aie-max-freq = <1250>;
		xlnx,aie-gen = /bits/ 8 <0x1>;
		xlnx,name-mi-axis = "M00_AXIS,M01_AXIS,M02_AXIS,";
		xlnx,fifo-type-si-axis = "S00_AXIS{FIFO_TYPE , 0}:S01_AXIS{FIFO_TYPE , 0}:S02_AXIS{FIFO_TYPE , 0}";
		xlnx,mem-rows = /bits/ 8 <0 0>;
		xlnx,mi-destid-pins;
		xlnx,ip-name = "ai_engine";
		#size-cells = <2>;
		xlnx,num-si-axi = <1>;
		xlnx,fast-pm-write;
		reg = <0x00000200 0x00000000 0x00000001 0x00000000>;
		clocks = <&misc_clk_1>;
		xlnx,num-noc-axis-clks = <0>;
		xlnx,auto-pipeline-mi-axis = "M00_AXIS{AUTO_PIPELINE , 0}:M01_AXIS{AUTO_PIPELINE , 0}:M02_AXIS{AUTO_PIPELINE , 0}";
		ranges;
		xlnx,num-clks = <1>;
		xlnx,partition-enabled = <0>;
		#address-cells = <2>;
		xlnx,num-si-axis = <3>;
		xlnx,name-mi-axi = "M00_AXI";
		xlnx,num-column = <1>;
		xlnx,aie-core-ref-ctrl-freqmhz = <1250>;
		xlnx,clk-names = "aclk0,";
		xlnx,name-si-axis = "S00_AXIS,S01_AXIS,S02_AXIS,";
		xlnx,fast-dm-write;
		xlnx,edk-iptype = "PERIPHERAL";
		xlnx,selected-nsu = <0>;
		power-domains = <&versal_firmware 0x18800000>;
		clock-names = "aclk0";
		xlnx,num-trig-in = <0>;
		xlnx,en-ext-rst = <1>;
		xlnx,auto-pipeline-si-axis = "S00_AXIS{AUTO_PIPELINE , 0}:S01_AXIS{AUTO_PIPELINE , 0}:S02_AXIS{AUTO_PIPELINE , 0}";
		xlnx,num-trig-out = <0>;
		xlnx,fifo-type-mi-axis = "M00_AXIS{FIFO_TYPE , 0}:M01_AXIS{FIFO_TYPE , 0}:M02_AXIS{FIFO_TYPE , 0}";
		xlnx,core-rows = /bits/ 8 <1 3>;
		xlnx,shim-rows = /bits/ 8 <0 1>;
		xlnx,name-si-axi = "S00_AXI";
		xlnx,start-column = <0>;
		xlnx,name = "ai_engine_0";
		xlnx,aie-site = "AIE";
		aie_aperture_0: aie_aperture@20000000000 {
			xlnx,device-name = <0>;
			interrupt-parent = <&gic>;
			interrupts = <0x0 0x94 0x4>, <0x0 0x95 0x4>, <0x0 0x96 0x4>;
			#address-cells = <2>;
			power-domains = <&versal_firmware 0x18800000>;
			xlnx,node-id = <0x18800000>;
			#size-cells = <2>;
			interrupt-names = "interrupt1" , "interrupt2" , "interrupt3";
			reg = <0x00000200 0x00000000 0x00000001 0x00000000>;
			xlnx,columns = < 0 42 >;
		};
	};
	aie_core_ref_clk_0: aie_core_ref_clk_0 {
		compatible = "fixed-clock";
		clock-frequency = <1250000000>;
		#clock-cells = <0>;
	};
};
